# tviic2d6mddr register map
Vendor: Cypress Semiconductor; Series: tviic2d6mddr; File version: 1.0
CPU: CM7 r0p1, little endian, MPU, FPU, VTOR, 3 interrupt priority bits
Registers are 32-bit, read-write, reset 0x0 unless marked. A register's access mark holds for its fields unless they carry their own. Offsets are from the block's base; [hi:lo] are bit positions; lines under a group give offsets from that group; {n}, {i} and the like mark numbered series.

## VIDEOSS0 (part 14 of 18) — Video and Graphics Subsystem IP
Base 0x40A00000
0x80000 VIDEOIO group — Video I/O Core
  0x24000 DISENG1 group — Display Engine
    0x2000 FRAMEGEN1 group — Frame Generator
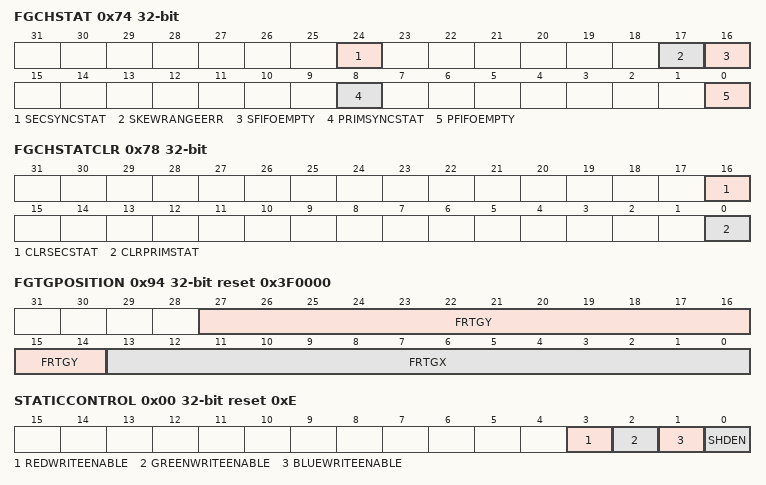
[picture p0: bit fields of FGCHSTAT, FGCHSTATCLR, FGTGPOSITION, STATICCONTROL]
      0x74 FGCHSTAT ro — FrameGen Channel Status Register
        [24] SECSYNCSTAT — Current status secondary channel synchronization (0 = out of sync, 1 = in sync; not locked).
        [17] SKEWRANGEERR — The secondary channel skew value has run out of the limit defined by SyncRangeLow and SyncRangeHigh. (bit locked when 1, clear by using ClrSecStat).
        [16] SFIFOEMPTY — Read request to empty secondary pixel FIFO detected. (bit locked when 1, clear by using ClrSecStat).
        [8] PRIMSYNCSTAT — Current status primary channel synchronization (0 = out of sync (frame tearing), 1 = in sync (normal operation); not locked).
        [0] PFIFOEMPTY — Read request to empty primary pixel FIFO detected. (Bit locked when 1, clear by using ClrPrimStat).
      0x78 FGCHSTATCLR wo reset not defined — FrameGen Channel Status Clear Register
        [16] CLRSECSTAT — Clears SFifoEmpty and SkewRangeErr in FgChStat register.
        [0] CLRPRIMSTAT — Clears PFifoEmpty in FgChStat register.
      0x7C FGSKEWMON ro — FrameGen Skew Monitor Register for Secondary Channel Skew Control
        [28:0] SKEWMON — Current skew value monitor for secondary channel skew control. Updated with hlast. (For debugging purposes only).
      0x80 FGSFIFOMIN ro reset not defined — FrameGen Secondary FIFO Min Fill Register
        [10:0] SFIFOMIN — Shows the minimal fill level of the secondary channel pixel FIFO. (For debugging purposes only).
      0x84 FGSFIFOMAX ro reset not defined — FrameGen Secondary FIFO Max Fill Register
        [10:0] SFIFOMAX — Shows the maximal fill level of the secondary channel pixel FIFO. (For debugging purposes only).
      0x88 FGSFIFOFILLCLR wo reset not defined — FrameGen Secondary FIFO Fill Clear Register
        [0] SFIFOFILLCLR — Write for clearing register FgSFifoMin and FgSFifoMax. (For debugging purposes only).
      0x8C FGSREPD ro — FrameGen Skew Regulation ExtraPolation Debug Register
        [28:0] EPVAL — Calculated value for line skew extrapolation in blanking. Updated with condition 'hlast AND vlast'. (For debugging purposes only)
      0x90 FGSRFTD ro — FrameGen Skew Regulation Frame Total Debug Register
        [27:0] FRTOT — Measured value for frame total measured in display clock cycles. Updated with condition 'hlast AND vlast' when first FrTot value is valid. (For debugging purposes only)
      0x94 FGTGPOSITION ro reset 0x3F0000 — Current (x,y) positions of the timing generator register in FrameGen timing generator.
        [27:14] FRTGY — Coordinated line position starting from VACT inside a total frame generated in timing generator in display clock cycles. (For debugging purposes only)
        [13:0] FRTGX — Coordinated pixel position starting from HACT inside a total line generated in timing generator in display clock cycles. (For debugging purposes only)
    0x2400 GAMMACOR1 group — Gamma Correction Unit 1
      0x00 STATICCONTROL reset 0xE — Static control settings.
        [3] REDWRITEENABLE — Write enable for the red color sampling point entries.
        [2] GREENWRITEENABLE — Write enable for the green color sampling point entries.
        [1] BLUEWRITEENABLE — Write enable for the blue color sampling point entries.
        [0] SHDEN — Enables shadowing of all RWS type registers (0=write_through, 1=shadowed).
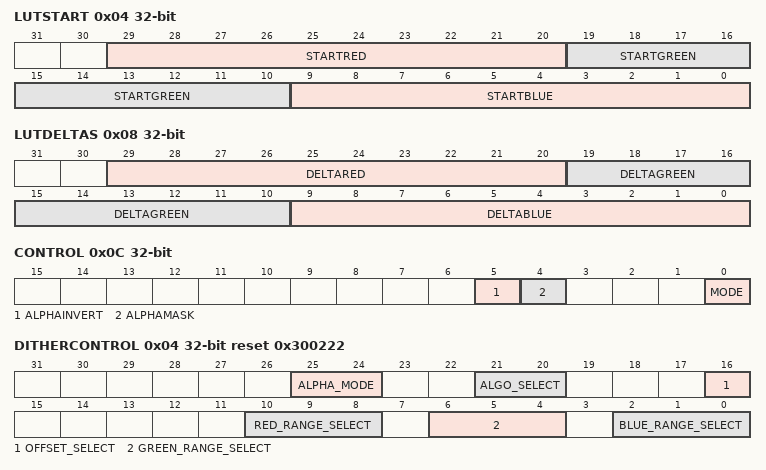
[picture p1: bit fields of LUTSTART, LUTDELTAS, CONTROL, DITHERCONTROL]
      0x04 LUTSTART wo — Start values for look-up table programming.
        [29:20] STARTRED — Start value for red or luma (Y) channel. (format is unsigned integer)
        [19:10] STARTGREEN — Start value for green or chroma (U) channel. (format is unsigned integer)
        [9:0] STARTBLUE — Start value for blue or chroma (V) channel. (format is unsigned integer)
      0x08 LUTDELTAS wo reset not defined — Delta values for look-up table programming.
        [29:20] DELTARED — Delta value for red or luma (Y) channel. (format is signed integer)
        [19:10] DELTAGREEN — Delta value for green or chroma (U) channel. (format is signed integer)
        [9:0] DELTABLUE — Delta value for blue or chroma (V) channel. (format is signed integer)
      0x0C CONTROL — Dynamic control settings.
        [5] ALPHAINVERT — Value 1 inverts the effect of the alpha mask mode when enabled (pixels with alpha value greater or equal 0.5 are by-passed).
        [4] ALPHAMASK — Value 1 enables the alpha mask mode. In this mode all pixels with an alpha value smaller than 0.5 are by-passed unchanged.
        [0] MODE — Operation mode for gamma correction unit
          0=NEUTRAL (Module in neutral mode, input data is bypassed to the output.); 1=GAMMACOR (Module in gamma correction mode.)
    0x2800 DITHER1 group — Dither Unit
      0x00 CONTROL — Dither Unit common control.
        [0] MODE — Mode which switches Dither Unit on/off. (format is unsigned integer)
          0=NEUTRAL (Neutral mode. Pixels by-pass the Dither Unit, all other settings are ignored.); 1=ACTIVE (Dither Unit is active.)
      0x04 DITHERCONTROL reset 0x300222 — Dither Unit processing control.
        [25:24] ALPHA_MODE — Enables/disables that dithering can be switched by alpha bit. (format is unsigned integer)
          0=DISABLE (The alpha bit is not considered.); 1=ENABLE_BY1 (Red, green and blue components are only dithered, if the alpha bit is 1.); 2=ENABLE_BY0 (Red, green and blue components are only dithered, if the alpha bit is 0.)
        [21:20] ALGO_SELECT — The number of output colors that can virtually be displayed by dithering is slightly lower than the number of physical input colors. This field selects how the mapping is done. (format is unsigned integer)
          1=NO_CORRECTION (Best possible resolution for most dark colors. Adds a diminutive offset to overall image brightness.); 2=BRIGHTNESS_CORRECTION (Preserves overall image brightness. Cannot resolve most dark and most bright colors. All codes in-between are distributed perfectly smooth.); 3=CONTRAST_CORRECTION (Preserves overall image brightness. Best possible distribution of color codes over complete range.)
        [16] OFFSET_SELECT — Selects the method how the dither offset is calculated. (format is unsigned integer)
          0=OFFS_SPATIAL (Offset is a bayer matrix value, which is selected according to pixel frame position.); 1=OFFS_TEMPORAL (Offset is the sum from a bayer matrix value, which is selected according to pixel frame position, and a value from a regular sequence, which changes each frame.)
        [10:8] RED_RANGE_SELECT — Mode which sets the reduction of component widths. (format is unsigned integer)
          2=RED_10TO8 (Reduces red component width from 10 bit to 8bit.); 3=RED_10TO7 (Reduces red component width from 10 bit to 7bit.); 4=RED_10TO6 (Reduces red component width from 10 bit to 6bit.); 5=RED_10TO5 (Reduces red component width from 10 bit to 5bit.)
        [6:4] GREEN_RANGE_SELECT — Mode which sets the reduction of component widths. (format is unsigned integer)
          2=GREEN_10TO8 (Reduces green component width from 10 bit to 8bit.); 3=GREEN_10TO7 (Reduces green component width from 10 bit to 7bit.); 4=GREEN_10TO6 (Reduces green component width from 10 bit to 6bit.); 5=GREEN_10TO5 (Reduces green component width from 10 bit to 5bit.)
        [2:0] BLUE_RANGE_SELECT — Mode which sets the reduction of component widths. (format is unsigned integer)
          2=BLUE_10TO8 (Reduces blue component width from 10 bit to 8bit.); 3=BLUE_10TO7 (Reduces blue component width from 10 bit to 7bit.); 4=BLUE_10TO6 (Reduces blue component width from 10 bit to 6bit.); 5=BLUE_10TO5 (Reduces blue component width from 10 bit to 5bit.)
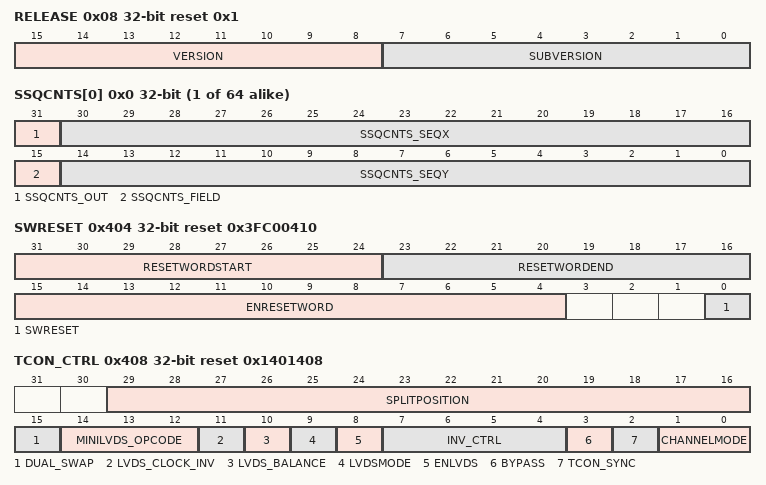
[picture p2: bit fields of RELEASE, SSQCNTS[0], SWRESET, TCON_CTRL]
      0x08 RELEASE ro reset 0x1 — Dither Unit release.
        [15:8] VERSION — Dither Unit version. (format is unsigned integer)
        [7:0] SUBVERSION — Dither Unit subversion. (format is unsigned integer)
    0x3000 TCON1 group — Timing Controller
      {0x0+4l} SSQCNTS[{l}] (l=0..63) reset not defined — The 64 Sequencer Position Definitions registers define the X/Y scan positions of the sequencers, hold their output value and assign the sequencer to an odd/even field
        [31] SSQCNTS_OUT — This bit holds the value (0,1) to be output when the X/Y scan position is reached.
        [30:16] SSQCNTS_SEQX — X scan position
        [15] SSQCNTS_FIELD — Field 0b=odd field, 1b=even field
        [14:0] SSQCNTS_SEQY — Y scan position
      0x400 SSQCYCLE — This bitfield sets the sequencer cycle length. The value set here -1 is the number of sequencer cycles
        [5:0] SSQCYCLE — Sequencer cycle length (number -1) of sequencer cycles
      0x404 SWRESET reset 0x3FC00410 — TCON Software Reset - Reset all tcon registers except configuration registers. Detailed description in specification document Note 1/ if tsig[11] pulse=n*pixel_period, (n-1)*0xFF will be blended between ResetWordStart and ResetWordEnd into miniLVDS stream Note 2/ if( EnResetWord=0) Reset-Pulse (ResetWordStart,ResetWordEnd) won't be blended into miniLVDS stream. Pixels will be transferred unchanged
        [31:24] RESETWORDSTART — 8-Bits value, that will be blended on rising edge of tsig[11] into miniLVDS stream
        [23:16] RESETWORDEND — 8-Bits value, that will be blended on falling edge of tsig[11] into miniLVDS stream
        [15:4] ENRESETWORD — Enable to blend ResetWord into miniLVDS stream EnResetWord[5-0] mapped to enable Blending Reset Pulse to [RLV5.RLV0]. EnResetWord[11-6] mapped to enable Blending Reset Pulse to [LLV5.LLV0].
        [0] SWRESET — Software reset
          0=OPERATION (operation mode); 1=SWRESET (So long SWReset = 0x1 tcon is in 'SW reset state' and it is released by internal logic (SWReset is released and end of frame arrived), read 0b reset not active 1b reset active (that means NO pixel of video frame is excepted until 'SW reset state' is released))
      0x408 TCON_CTRL reset 0x1401408 — TCON Control register
        [29:16] SPLITPOSITION — Index of first column of right display half when ChannelMode is DUAL_SPLIT. SplitPosition and (Hact - SplitPosition) must be less or equal than half of the max supported active frame width. If SplitPosition is greater than (Hact - SplitPosition), then Htotal must be greater than 2*SplitPosition; else Htotal must be greater than 2*(Hact - SplitPosition). Once setting a SplitPosition, data_en is needed. The SplitPosition must be even.
        [15] DUAL_SWAP — pixels of lower/upper channel can be swapped if tcon operates in DUAL-mode (include LVDS/miniLVDS) no effect in SINGLE-mode
          1=SWAP (swapping pixels between lower-channel and upper-channel); 0=NON_SWAP (NON-swapping pixels between lower-channel and upper-channel)
        [14:12] MINILVDS_OPCODE — Operation mode of MiniLVDS
          0=MODE_3PAIRS (MiniLVDS operates in 6 and 8 bit data, three pairs); 1=MODE_4PAIRS (Not Implemented); 2=MODE_5PAIRS (Not Implemented); 3=MODE_6PAIRS (MiniLVDS operates in 6 and 8 bit data, six pairs); {v}=RSVD{v-3} (N/A) (v=4..7)
        [11] LVDS_CLOCK_INV — Inversion the polarity of lvds clock in OpenLDI Mode
          1=INV (Invert LVDS Clock); 0=NON_INV (NON-Invert LVDS Clock)
        [10] LVDS_BALANCE — Operation mode of LVDS-OpenLDI
          1=BALANCED (LVDS operates in 24 bits Balanced Mode); 0=UNBALANCED (LVDS operates in 24 bits Unbalanced Mode)
        [9] LVDSMODE — Selection the LVDS Mode if EnLVDS = ENABLE_LVDS
          1=MINI_LVDS; 0=LVDS (LVDS Mode, refer to OpenLDI)
        [8] ENLVDS — Enable LVDS Mode
          1=ENABLE_LVDS (Enable LVDS , TTL and RSDS are disable); 0=DISABLE_LVDS (Disable LVDS, Enable TTL and RSDS)
        [7:4] INV_CTRL — Minimize the toggle rate of tcon output for display panel, that supports data inversion control. Otherwise set Inv_Ctrl = 0. Valid for all channels . Inv_Ctrl does not effect any function on LVDS-Output.
          0=DISABLE (Disable inversion control); 1=RGB_2_BITS (Enable inversion control for number of RGB-Bits = 2); 2=RGB_4_BITS (Enable inversion control for number of RGB-Bits = 4); 3=RGB_6_BITS (Enable inversion control for number of RGB-Bits = 6); 4=RGB_8_BITS (Enable inversion control for number of RGB-Bits = 8); 5=RGB_10_BITS (Enable inversion control for number of RGB-Bits = 10); 6=RGB_12_BITS (Enable inversion control for number of RGB-Bits = 12); 7=RGB_14_BITS (Enable inversion control for number of RGB-Bits = 14); 8=RGB_16_BITS (Enable inversion control for number of RGB-Bits = 16); 9=RGB_18_BITS (Enable inversion control for number of RGB-Bits = 18); 10=RGB_20_BITS (Enable inversion control for number of RGB-Bits = 20); 11=RGB_22_BITS (Enable inversion control for number of RGB-Bits = 22); 12=RGB_24_BITS (Enable inversion control for number of RGB-Bits = 24); 13=RSVD1 (N/A); 14=RSVD2 (N/A); 15=RSVD3 (N/A)
        [3] BYPASS — Bypassing synchronization
          0=TCON_MODE (tcon operation mode); 1=BYPASS_MODE (tcon in Bypass mode. input pixel and its sync-signals are bypassed to tcon-output)
        [2] TCON_SYNC — Select synchronization between hsync/vsync and hlast/vlast
          0=H_VLAST (tcon timing generator synchronized to hlast, vlast); 1=H_VSYNC (tcon timing generator synchronized to hsync, vsync where horizontal synchronization is synchronized at the falling edge of hsync)
        [1:0] CHANNELMODE — Selects one of tcon operation modes, SINGLE, DUAL_INTERLEAVED or DUAL_SPLIT. If MiniLVDS operation is selected (EnLVDS = ENABLE_LVDS and LVDSMode = Mini_LVDS), tcon operates in MiniLVDS mode, independent of ChannelMode programming. SplitPosition must be specified in MiniLVDS operation in DUAL_INTERLEAVED or DUAL_SPLIT mode, the horizontal parameter of signal generator have to set twice as they are specified in the panel-specification (panel 320, tsig_start 0, tsig_stop 320 on DUAL-Mode tsig_start 0, tsig_stop 640 ... (SplitPosition is automatically adjusted) )
          0=SINGLE (Single pixel mode. Both channels channel are active at full pixel clock. If bitmap of both panels are the same, both panels are identical); 1=DUAL_INTERLEAVED (Dual pixel mode. Both channels are active at half the pixel clock. 1st channel drives display columns with even and 2nd one with odd index.); 2=DUAL_SPLIT (Dual pixel mode. Both channels are active at half the pixel clock. 1st channel drives the left and 2nd one the right half of the display. Note data_en is needed in this mode)
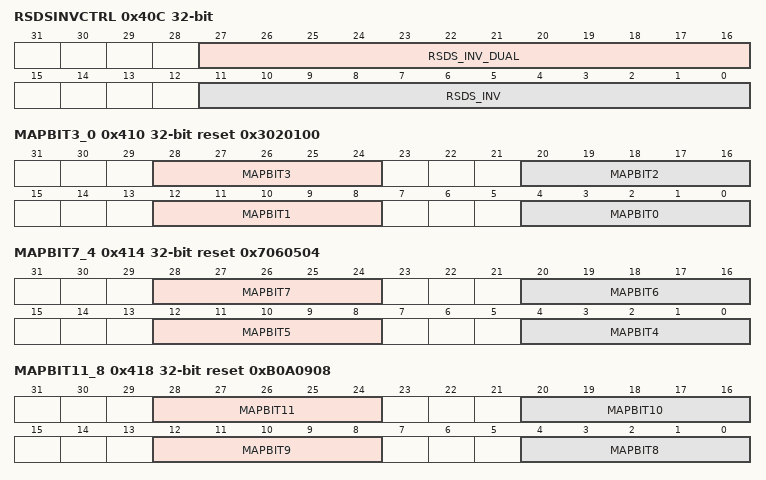
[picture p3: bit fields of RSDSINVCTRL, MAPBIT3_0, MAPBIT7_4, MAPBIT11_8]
      0x40C RSDSINVCTRL — Controls inversion of output polarity when connected IO cells operate in RSDS mode
        [27:16] RSDS_INV_DUAL — Same as RSDS_inv for 2nd channel
        [11:0] RSDS_INV — Inversion vector for 1st channel. For i in [ 0 .. 11 ]; if RSDS_Inv [ i ] == 0 => NON-Inversion of RSDS [ i ] else Inversion of RSDS [ i ]
      0x410 MAPBIT3_0 reset 0x3020100 — Mapping of 24 bit RGB or Timing Generator TSig[5-0] to bit 0 .. 3
        [28:24] MAPBIT3 — map bit[ 3 ] from [ Blue, Green, Red ] or from TSig[5-0]. If MapBit3 in [ 23..0 ] => bit[ 3 ] = [ Blue, Green, Red ] [ MapBit3 ]; if MapBit3 in [29 .. 24] => bit[ 3 ] in { TSig[5] .. TSig[0] }; If MapBit3 = 31 => bit[ 3 ] = 0 ; if MapBit3= 30 => bit[ 3 ] = 1
        [20:16] MAPBIT2 — map bit[ 2 ] from [ Blue, Green, Red ] or from TSig[5-0]. If MapBit2 in [ 23..0 ] => bit[ 2 ] = [ Blue, Green, Red ] [ MapBit2 ]; if MapBit2 in [29 .. 24] => bit[ 2 ] in { TSig[5] .. TSig[0] }; If MapBit2 = 31 => bit[ 2 ] = 0 ; if MapBit2= 30 => bit[ 2 ] = 1
        [12:8] MAPBIT1 — map bit[ 1 ] from [ Blue, Green, Red ] or from TSig[5-0]. If MapBit1 in [ 23..0 ] => bit[ 1 ] = [ Blue, Green, Red ] [ MapBit1 ]; if MapBit1 in [29 .. 24] => bit[ 1 ] in { TSig[5] .. TSig[0] }; If MapBit1 = 31 => bit[ 1 ] = 0 ; if MapBit1= 30 => bit[ 1 ] = 1
        [4:0] MAPBIT0 — map bit[ 0 ] from [ Blue, Green, Red ] or from TSig[5-0]. If MapBit0 in [ 23..0 ] => bit[ 0 ] = [ Blue, Green, Red ] [ MapBit0 ]; if MapBit0 in [29 .. 24] => bit[ 0 ] in { TSig[5] .. TSig[0] }; If MapBit0 = 31 => bit[ 0 ] = 0 ; if MapBit1= 30 => bit[ 0 ] = 1
      0x414 MAPBIT7_4 reset 0x7060504 — Mapping of 24 bit RGB or Timing Generator TSig[5-0] to bit 4 .. 7
        [28:24] MAPBIT7 — map bit[ 7 ] from [ Blue, Green, Red ] or from TSig[5-0]. If MapBit7 in [ 23..0 ] => bit[ 7 ] = [ Blue, Green, Red ] [ MapBit7 ]; if MapBit7 in [29 .. 24] => bit[ 7 ] in { TSig[5] .. TSig[0] }; If MapBit7 = 31 => bit[ 7 ] = 0 ; if MapBit7= 30 => bit[ 7 ] = 1
        [20:16] MAPBIT6 — map bit[ 6 ] from [ Blue, Green, Red ] or from TSig[5-0]. If MapBit6 in [ 23..0 ] => bit[ 6 ] = [ Blue, Green, Red ] [ MapBit6 ]; if MapBit6 in [29 .. 24] => bit[ 6 ] in { TSig[5] .. TSig[0] }; If MapBit6 = 31 => bit[ 6 ] = 0 ; if MapBit6= 30 => bit[ 6 ] = 1
        [12:8] MAPBIT5 — map bit[ 5 ] from [ Blue, Green, Red ] or from TSig[5-0]. If MapBit5 in [ 23..0 ] => bit[ 5 ] = [ Blue, Green, Red ] [ MapBit5 ]; if MapBit5 in [29 .. 24] => bit[ 5 ] in { TSig[5] .. TSig[0] }; If MapBit5 = 31 => bit[ 5 ] = 0 ; if MapBit5= 30 => bit[ 5 ] = 1
        [4:0] MAPBIT4 — map bit[ 4 ] from [ Blue, Green, Red ] or from TSig[5-0]. If MapBit4 in [ 23..0 ] => bit[ 4 ] = [ Blue, Green, Red ] [ MapBit4 ]; if MapBit4 in [29 .. 24] => bit[ 4 ] in { TSig[5] .. TSig[0] }; If MapBit4 = 31 => bit[ 4 ] = 0 ; if MapBit4= 30 => bit[ 4 ] = 1
      0x418 MAPBIT11_8 reset 0xB0A0908 — Mapping of 24 bit RGB or Timing Generator TSig[5-0] to bit 8 .. 11
        [28:24] MAPBIT11 — map bit[ 11 ] from [ Blue, Green, Red ] or from TSig[5-0]. If MapBit11 in [ 23..0 ] => bit[ 11 ] = [ Blue, Green, Red ] [ MapBit11 ]; if MapBit11 in [29 .. 24] => bit[ 11 ] in { TSig[5] .. TSig[0] } ; If MapBit11 = 31 => bit[ 11 ] = 0 ; if MapBit11= 30 => bit[ 11 ] = 1
        [20:16] MAPBIT10 — map bit[ 10 ] from [ Blue, Green, Red ] or from TSig[5-0]. If MapBit10 in [ 23..0 ] => bit[ 10 ] = [ Blue, Green, Red ] [ MapBit10 ]; if MapBit10 in [29 .. 24] => bit[ 10 ] in { TSig[5] .. TSig[0] } ; If MapBit10 = 31 => bit[ 10 ] = 0 ; if MapBit10= 30 => bit[ 10 ] = 1
        [12:8] MAPBIT9 — map bit[ 9 ] from [ Blue, Green, Red ] or from TSig[5-0]. if MapBit9 in [ 23..0 ] => bit[ 9 ] = [ Blue, Green, Red ] [ MapBit9 ]; if MapBit9 in [29 .. 24] => bit[ 9 ] in { TSig[5] .. TSig[0] }; If MapBit9 = 31 => bit[ 9 ] = 0 ; if MapBit9= 30 => bit[ 9 ] = 1
        [4:0] MAPBIT8 — map bit[ 8 ] from [ Blue, Green, Red ] or from TSig[5-0]. if MapBit8 in [ 23..0 ] => bit[ 8 ] = [ Blue, Green, Red ] [ MapBit8 ]; if MapBit8 in [29 .. 24] => bit[ 8 ] in { TSig[5] .. TSig[0] }; If MapBit8 = 31 => bit[ 8 ] = 0 ; if MapBit8= 30 => bit[ 8 ] = 1
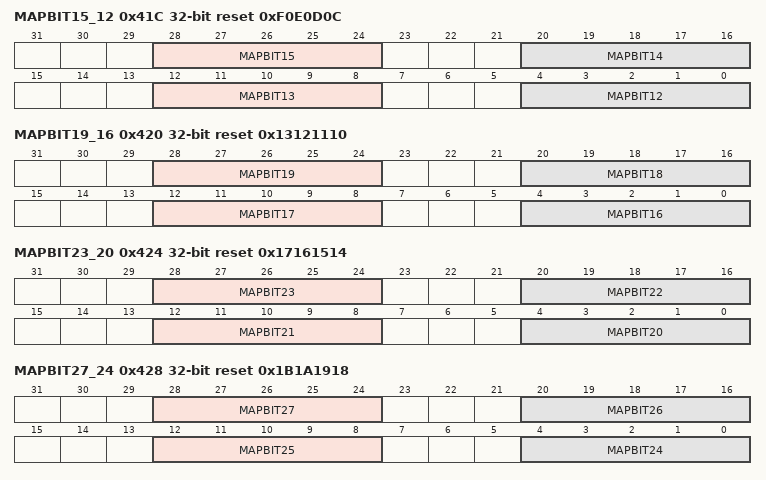
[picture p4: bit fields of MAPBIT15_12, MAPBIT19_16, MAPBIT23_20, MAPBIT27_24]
      0x41C MAPBIT15_12 reset 0xF0E0D0C — Mapping of 24 bit RGB or Timing Generator TSig[5-0] to bit 12 .. 15
        [28:24] MAPBIT15 — map bit[ 15 ] from [ Blue, Green, Red ] or from TSig[5-0]. If MapBit15 in [ 23..0 ] => bit[ 15 ] = [ Blue, Green, Red ] [ MapBit15 ]; if MapBit15 in [29 .. 24] => bit[ 15 ] in { TSig[5] .. TSig[0] } ; If MapBit15 = 31 => bit[ 15 ] = 0 ; if MapBit15= 30 => bit[ 15 ] = 1
        [20:16] MAPBIT14 — map bit[ 14 ] from [ Blue, Green, Red ] or from TSig[5-0]. If MapBit14 in [ 23..0 ] => bit[ 14 ] = [ Blue, Green, Red ] [ MapBit14 ]; if MapBit14 in [29 .. 24] => bit[ 14 ] in { TSig[5] .. TSig[0] } ; If MapBit14 = 31 => bit[ 14 ] = 0 ; if MapBit14= 30 => bit[ 14 ] = 1
        [12:8] MAPBIT13 — map bit[ 13 ] from [ Blue, Green, Red ] or from TSig[5-0]. If MapBit13 in [ 23..0 ] => bit[ 13 ] = [ Blue, Green, Red ] [ MapBit13 ]; if MapBit13 in [29 .. 24] => bit[ 13 ] in { TSig[5] .. TSig[0] } ; If MapBit13 = 31 => bit[ 13 ] = 0 ; if MapBit13= 30 => bit[ 13 ] = 1
        [4:0] MAPBIT12 — map bit[ 12 ] from [ Blue, Green, Red ] or from TSig[5-0]. If MapBit12 in [ 23..0 ] => bit[ 12 ] = [ Blue, Green, Red ] [ MapBit12 ]; if MapBit12 in [29 .. 24] => bit[ 12 ] in { TSig[5] .. TSig[0] } ; If MapBit12 = 31 => bit[ 12 ] = 0 ; if MapBit12= 30 => bit[ 12 ] = 1
      0x420 MAPBIT19_16 reset 0x13121110 — Mapping of 24 bit RGB or Timing Generator TSig[5-0] to bit 16 .. 19
        [28:24] MAPBIT19 — map bit[ 19 ] from [ Blue, Green, Red ] or from TSig[5-0]. If MapBit19 in [ 23..0 ] => bit[ 19 ] = [ Blue, Green, Red ] [ MapBit19 ]; if MapBit19 in [29 .. 24] => bit[ 19 ] in { TSig[5] .. TSig[0] } ; If MapBit19 = 31 => bit[ 19 ] = 0 ; if MapBit19= 30 => bit[ 19 ] = 1
        [20:16] MAPBIT18 — map bit[ 18 ] from [ Blue, Green, Red ] or from TSig[5-0]. If MapBit18 in [ 23..0 ] => bit[ 18 ] = [ Blue, Green, Red ] [ MapBit18 ]; if MapBit18 in [29 .. 24] => bit[ 18 ] in { TSig[5] .. TSig[0] } ; If MapBit18 = 31 => bit[ 18 ] = 0 ; if MapBit18= 30 => bit[ 18 ] = 1
        [12:8] MAPBIT17 — map bit[ 17 ] from [ Blue, Green, Red ] or from TSig[5-0]. If MapBit17 in [ 23..0 ] => bit[ 17 ] = [ Blue, Green, Red ] [ MapBit17 ]; if MapBit17 in [29 .. 24] => bit[ 17 ] in { TSig[5] .. TSig[0] } ; If MapBit17 = 31 => bit[ 17 ] = 0 ; if MapBit17= 30 => bit[ 17 ] = 1
        [4:0] MAPBIT16 — map bit[ 16 ] from [ Blue, Green, Red ] or from TSig[5-0]. If MapBit16 in [ 23..0 ] => bit[ 16 ] = [ Blue, Green, Red ] [ MapBit16 ]; if MapBit16 in [29 .. 24] => bit[ 16 ] in { TSig[5] .. TSig[0] } ; If MapBit16 = 31 => bit[ 16 ] = 0 ; if MapBit16= 30 => bit[ 16 ] = 1
      0x424 MAPBIT23_20 reset 0x17161514 — Mapping of 24 bit RGB or Timing Generator TSig[5-0] to bit 20 .. 23
        [28:24] MAPBIT23 — map bit[ 23 ] from [ Blue, Green, Red ] or from TSig[5-0]. If MapBit23 in [ 23..0 ] => bit[ 23 ] = [ Blue, Green, Red ] [ MapBit23 ]; if MapBit23 in [29 .. 24] => bit[ 23 ] in { TSig[5] .. TSig[0] } ; If MapBit23 = 31 => bit[ 23 ] = 0 ; if MapBit23= 30 => bit[ 23 ] = 1
        [20:16] MAPBIT22 — map bit[ 22 ] from [ Blue, Green, Red ] or from TSig[5-0]. If MapBit22 in [ 23..0 ] => bit[ 22 ] = [ Blue, Green, Red ] [ MapBit22 ]; if MapBit22 in [29 .. 24] => bit[ 22 ] in { TSig[5] .. TSig[0] } ; If MapBit22 = 31 => bit[ 22 ] = 0 ; if MapBit22= 30 => bit[ 22 ] = 1
        [12:8] MAPBIT21 — map bit[ 21 ] from [ Blue, Green, Red ] or from TSig[5-0]. If MapBit21 in [ 23..0 ] => bit[ 21 ] = [ Blue, Green, Red ] [ MapBit21 ]; if MapBit21 in [29 .. 24] => bit[ 21 ] in { TSig[5] .. TSig[0] } ; If MapBit21 = 31 => bit[ 21 ] = 0 ; if MapBit21= 30 => bit[ 21 ] = 1
        [4:0] MAPBIT20 — map bit[ 20 ] from [ Blue, Green, Red ] or from TSig[5-0]. If MapBit20 in [ 23..0 ] => bit[ 20 ] = [ Blue, Green, Red ] [ MapBit20 ]; if MapBit20 in [29 .. 24] => bit[ 20 ] in { TSig[5] .. TSig[0] } ; If MapBit20 = 31 => bit[ 20 ] = 0 ; if MapBit20= 30 => bit[ 20 ] = 1
      0x428 MAPBIT27_24 reset 0x1B1A1918 — Mapping of 24 bit RGB or Timing Generator TSig[5-0] to bit 24 .. 27
        [28:24] MAPBIT27 — map bit[27] from [ Blue, Green, Red ] or from TSig[5-0]. If MapBit27 in [ 23..0 ] => bit[27] = [ Blue, Green, Red ] [ MapBit27 ]; if MapBit27 in [29 .. 24] => bit[27] in { TSig[5] .. TSig[0] } ; If MapBit27 = 31 => bit[27] = 0 ; if MapBit27= 30 => bit[27] = 1
        [20:16] MAPBIT26 — map bit[26] from [ Blue, Green, Red ] or from TSig[5-0]. If MapBit26 in [ 23..0 ] => bit[26] = [ Blue, Green, Red ] [ MapBit26 ]; if MapBit26 in [29 .. 24] => bit[26] in { TSig[5] .. TSig[0] } ; If MapBit26 = 31 => bit[26] = 0 ; if MapBit26= 30 => bit[26] = 1
        [12:8] MAPBIT25 — map bit[25] from [ Blue, Green, Red ] or from TSig[5-0]. If MapBit25 in [ 23..0 ] => bit[25] = [ Blue, Green, Red ] [ MapBit25 ]; if MapBit25 in [29 .. 24] => bit[25] in { TSig[5] .. TSig[0] } ; If MapBit25 = 31 => bit[25] = 0 ; if MapBit25= 30 => bit[25] = 1
        [4:0] MAPBIT24 — map bit[24] from [ Blue, Green, Red ] or from TSig[5-0]. If MapBit24 in [ 23..0 ] => bit[24] = [ Blue, Green, Red ] [ MapBit24 ]; if MapBit24 in [29 .. 24] => bit[24] in { TSig[5] .. TSig[0] } ; If MapBit24 = 31 => bit[24] = 0 ; if MapBit24= 30 => bit[24] = 1
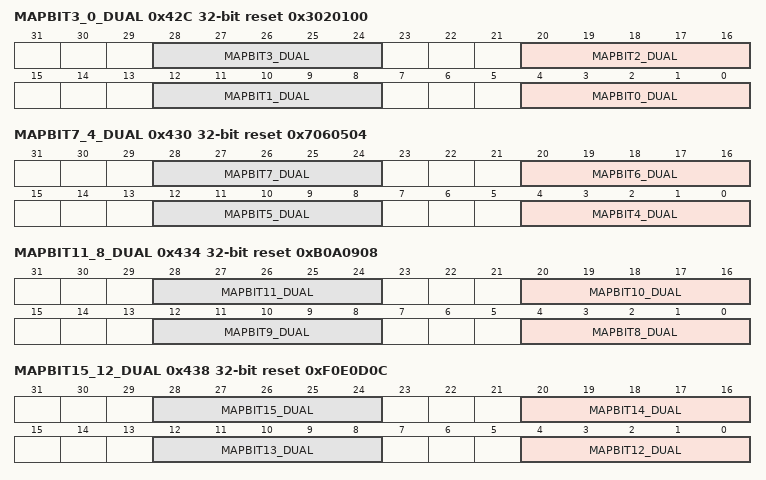
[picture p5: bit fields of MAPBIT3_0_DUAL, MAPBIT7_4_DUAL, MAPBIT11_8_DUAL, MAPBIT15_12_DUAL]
      0x42C MAPBIT3_0_DUAL reset 0x3020100 — Same as MapBit3_0 for 2nd channel
        [8n+4:8n] MAPBIT{n}_DUAL (n=0..3) — Same as MapBit{n} for 2nd channel
      0x430 MAPBIT7_4_DUAL reset 0x7060504 — Same as MapBit7_4 for 2nd channel
        [8n-28:8n-32] MAPBIT{n}_DUAL (n=4..7) — Same as MapBit{n} for 2nd channel
      0x434 MAPBIT11_8_DUAL reset 0xB0A0908 — Same as MapBit11_8 for 2nd channel
        [8n-60:8n-64] MAPBIT{n}_DUAL (n=8..11) — Same as MapBit{n} for 2nd channel
      0x438 MAPBIT15_12_DUAL reset 0xF0E0D0C — Same as MapBit15_12 for 2nd channel
        [8n-92:8n-96] MAPBIT{n}_DUAL (n=12..15) — Same as MapBit{n} for 2nd channel
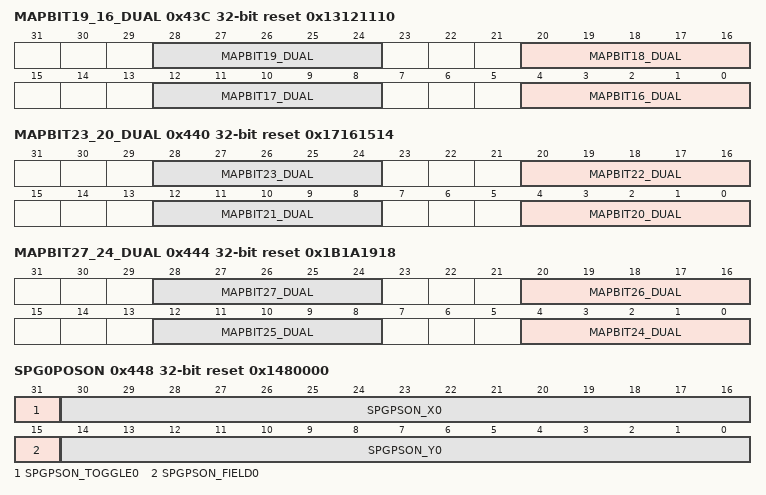
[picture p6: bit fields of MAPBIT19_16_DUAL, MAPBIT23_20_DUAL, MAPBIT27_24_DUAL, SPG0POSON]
      0x43C MAPBIT19_16_DUAL reset 0x13121110 — Same as MapBit19_16 for 2nd channel
        [8n-124:8n-128] MAPBIT{n}_DUAL (n=16..19) — Same as MapBit{n} for 2nd channel
      0x440 MAPBIT23_20_DUAL reset 0x17161514 — Same as MapBit23_20 for 2nd channel
        [8n-156:8n-160] MAPBIT{n}_DUAL (n=20..23) — Same as MapBit{n} for 2nd channel
      0x444 MAPBIT27_24_DUAL reset 0x1B1A1918 — Same as MapBit27_24 for 2nd channel
        [8n-188:8n-192] MAPBIT{n}_DUAL (n=24..27) — Same as MapBit{n} for 2nd channel
      0x448 SPG0POSON reset 0x1480000 — Sync pulse generator 0, 'Switch on' position
        [31] SPGPSON_TOGGLE0 — Toggle enable 0b=disable, 1b=enable
        [30:16] SPGPSON_X0 — X scan position
        [15] SPGPSON_FIELD0 — Field 0b=odd field, 1b=even field
        [14:0] SPGPSON_Y0 — Y scan position
      0x44C SPG0MASKON reset 0xFFFF — The Sequencer Pulse Generator 0 Mask Enable register is used to mask the enable of SPG 0
        [30:0] SPGMKON0 — Mask bits 0b=Include this bit in position matching, 1b= Do not include this bit in position matching
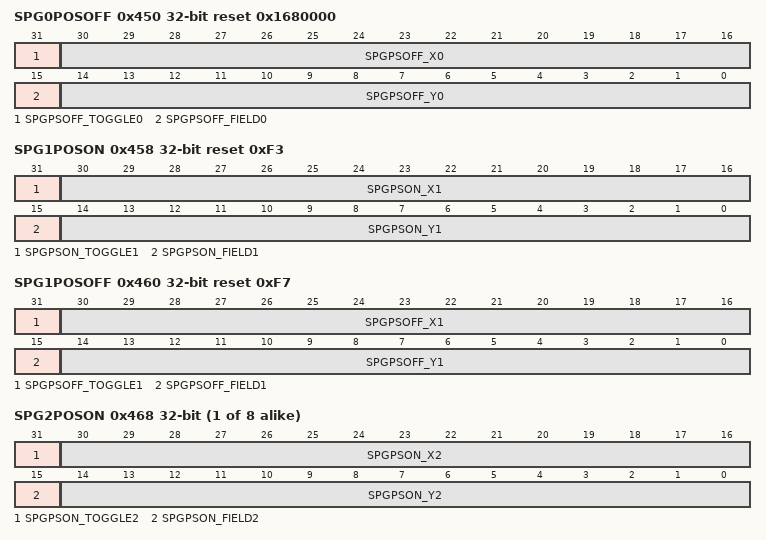
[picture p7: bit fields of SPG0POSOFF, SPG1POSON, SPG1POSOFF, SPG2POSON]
      0x450 SPG0POSOFF reset 0x1680000 — Sync pulse generator 0, 'Switch off' position
        [31] SPGPSOFF_TOGGLE0 — Toggle enable 0b=disable, 1b=enable
        [30:16] SPGPSOFF_X0 — X scan position
        [15] SPGPSOFF_FIELD0 — Field 0b=odd field, 1b=even field
        [14:0] SPGPSOFF_Y0 — Y scan position
      0x454 SPG0MASKOFF reset 0xFFFF — The Sequencer Pulse Generator 0 Mask Enable register is used to mask the disable of SPG 0
        [30:0] SPGMKOFF0 — Mask bits 0b=Include this bit in position matching, 1b= Do not include this bit in position matching
      0x458 SPG1POSON reset 0xF3 — Sync pulse generator 1, 'Switch on' position
        [31] SPGPSON_TOGGLE1 — Toggle enable 0b=disable, 1b=enable
        [30:16] SPGPSON_X1 — X scan position
        [15] SPGPSON_FIELD1 — Field 0b=odd field, 1b=even field
        [14:0] SPGPSON_Y1 — Y scan position
      0x45C SPG1MASKON reset 0x7FFF0000 — The Sequencer Pulse Generator 1 Mask Enable register is used to mask the enable of SPG 1
        [30:0] SPGMKON1 — mask bits (1= do not include this bit into position matching)
      0x460 SPG1POSOFF reset 0xF7 — Sync pulse generator 1, 'Switch off' position
        [31] SPGPSOFF_TOGGLE1 — Toggle enable 0b=disable, 1b=enable
        [30:16] SPGPSOFF_X1 — X scan position
        [15] SPGPSOFF_FIELD1 — Field 0b=odd field, 1b=even field
        [14:0] SPGPSOFF_Y1 — Y scan position
      0x464 SPG1MASKOFF reset 0x7FFF0000 — The Sequencer Pulse Generator 1 Mask Enable register is used to mask the disable of SPG 1
        [30:0] SPGMKOFF1 — Mask bits 0b=Include this bit in position matching, 1b= Do not include this bit in position matching
      {0x448+0x10*l} SPG{l}POSON (l=2..9) — Sync pulse generator {l}, 'Switch on' position
        [31] SPGPSON_TOGGLE{l} — Toggle enable 0b=disable, 1b=enable
        [30:16] SPGPSON_X{l} — X scan position
        [15] SPGPSON_FIELD{l} — Field 0b=odd field, 1b=even field
        [14:0] SPGPSON_Y{l} — Y scan position
      0x46C SPG2MASKON reset 0xFFFF — The Sequencer Pulse Generator 2 Mask Enable register is used to mask the enable of SPG 2
        [30:0] SPGMKON2 — Mask bits 0b=Include this bit in position matching, 1b= Do not include this bit in position matching
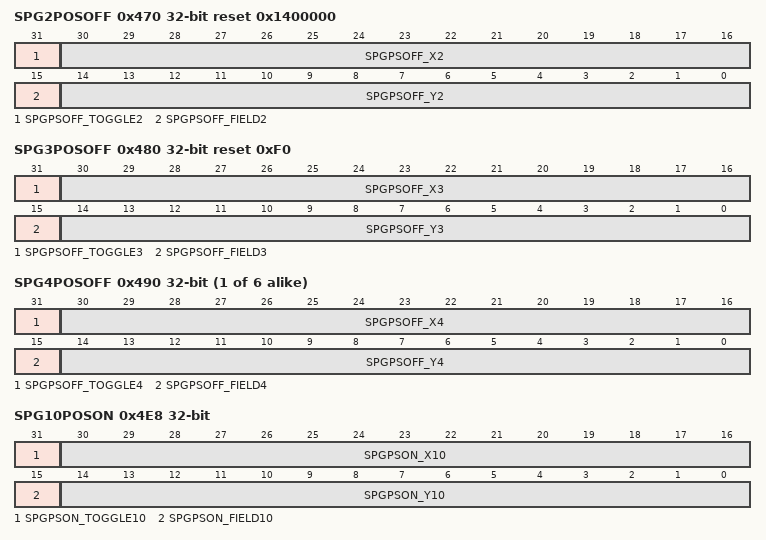
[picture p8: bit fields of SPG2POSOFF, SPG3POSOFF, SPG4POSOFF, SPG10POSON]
      0x470 SPG2POSOFF reset 0x1400000 — Sync pulse generator 2, 'Switch off' position
        [31] SPGPSOFF_TOGGLE2 — Toggle enable 0b=disable, 1b=enable
        [30:16] SPGPSOFF_X2 — X scan position
        [15] SPGPSOFF_FIELD2 — Field 0b=odd field, 1b=even field
        [14:0] SPGPSOFF_Y2 — Y scan position
      0x474 SPG2MASKOFF reset 0xFFFF — The Sequencer Pulse Generator 2 Mask Enable register is used to mask the disable of SPG 2
        [30:0] SPGMKOFF2 — Mask bits 0b=Include this bit in position matching, 1b= Do not include this bit in position matching
      0x47C SPG3MASKON reset 0x7FFF0000 — The Sequencer Pulse Generator 3 Mask Enable register is used to mask the enable of SPG 3
        [30:0] SPGMKON3 — Mask bits 0b=Include this bit in position matching, 1b= Do not include this bit in position matching
      0x480 SPG3POSOFF reset 0xF0 — Sync pulse generator 3, 'Switch off' position
        [31] SPGPSOFF_TOGGLE3 — Toggle enable 0b=disable, 1b=enable
        [30:16] SPGPSOFF_X3 — X scan position
        [15] SPGPSOFF_FIELD3 — Field 0b=odd field, 1b=even field
        [14:0] SPGPSOFF_Y3 — Y scan position
      0x484 SPG3MASKOFF reset 0x7FFF0000 — The Sequencer Pulse Generator 3 Mask Enable register is used to mask the disable of SPG 3
        [30:0] SPGMKOFF3 — Mask bits 0b=Include this bit in position matching, 1b= Do not include this bit in position matching
      {0x44C+0x10*l} SPG{l}MASKON (l=4..11) — The Sequencer Pulse Generator {l} Mask Enable register is used to mask the enable of SPG {l}
        [30:0] SPGMKON{l} — Mask bits 0b=Include this bit in position matching, 1b= Do not include this bit in position matching
      {0x450+0x10*l} SPG{l}POSOFF (l=4..9) — Sync pulse generator {l}, 'Switch off' position
        [31] SPGPSOFF_TOGGLE{l} — Toggle enable 0b=disable, 1b=enable
        [30:16] SPGPSOFF_X{l} — X scan position
        [15] SPGPSOFF_FIELD{l} — Field 0b=odd field, 1b=even field
        [14:0] SPGPSOFF_Y{l} — Y scan position
      {0x454+0x10*l} SPG{l}MASKOFF (l=4..11) — The Sequencer Pulse Generator {l} Mask Enable register is used to mask the disable of SPG {l}
        [30:0] SPGMKOFF{l} — Mask bits 0b=Include this bit in position matching, 1b= Do not include this bit in position matching
      0x4E8 SPG10POSON — Sync pulse generator 10, 'Switch on' position
        [31] SPGPSON_TOGGLE10 — toggle enable 0b=disable, 1b=enable
        [30:16] SPGPSON_X10 — X scan position
        [15] SPGPSON_FIELD10 — Field 0b=odd field, 1b=even field
        [14:0] SPGPSON_Y10 — Y scan position
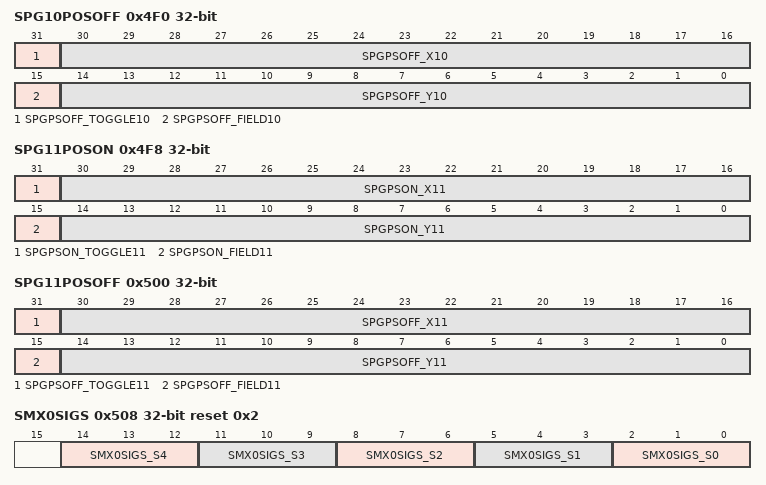
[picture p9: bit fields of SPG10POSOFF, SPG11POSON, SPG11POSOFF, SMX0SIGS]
      0x4F0 SPG10POSOFF — Sync pulse generator 10, 'Switch off' position
        [31] SPGPSOFF_TOGGLE10 — toggle enable 0b=disable, 1b=enable
        [30:16] SPGPSOFF_X10 — X scan position
        [15] SPGPSOFF_FIELD10 — Field 0b=odd field, 1b=even field
        [14:0] SPGPSOFF_Y10 — Y scan position
      0x4F8 SPG11POSON — Sync pulse generator 11, 'Switch on' position
        [31] SPGPSON_TOGGLE11 — toggle enable 0b=disable, 1b=enable
        [30:16] SPGPSON_X11 — X scan position
        [15] SPGPSON_FIELD11 — Field 0b=odd field, 1b=even field
        [14:0] SPGPSON_Y11 — Y scan position
      0x500 SPG11POSOFF — Sync pulse generator 11, 'Switch off' position
        [31] SPGPSOFF_TOGGLE11 — toggle enable 0b=disable, 1b=enable
        [30:16] SPGPSOFF_X11 — X scan position
        [15] SPGPSOFF_FIELD11 — Field 0b=odd field, 1b=even field
        [14:0] SPGPSOFF_Y11 — Y scan position
      0x508 SMX0SIGS reset 0x2 — Selection of input signals of sync mixer
        [3n+2:3n] SMX0SIGS_S{n} (n=0..4) — select {n} 000b=constant 0, 001b=sync sequencer output, 010b...111b sync pulse generator SPG0 .. SPG5
      0x50C SMX0FCTTABLE reset 0x1 — The sync mixer output is the result of the function table a=s4*2**4+s3*2**3+s2*2**2+s1*2**1+s0*2**0 whereby a is bit number and s result of sync mixer input selection
        [31:0] SMXFCT0 — Sync mixer 0 function table
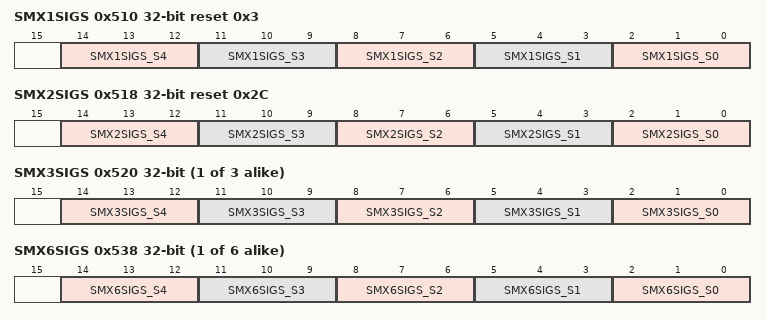
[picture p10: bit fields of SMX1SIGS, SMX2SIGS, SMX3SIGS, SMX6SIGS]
      0x510 SMX1SIGS reset 0x3 — Selection of input signals of sync mixer
        [3n+2:3n] SMX1SIGS_S{n} (n=0..4) — select {n} 000b=constant 0, 001b=sync sequencer output, 010b...111b sync pulse generator SPG0 .. SPG5
      0x514 SMX1FCTTABLE reset 0x1 — The sync mixer output is the result of the function table a=s4*2**4+s3*2**3+s2*2**2+s1*2**1+s0*2**0 whereby a is bit number and s result of sync mixer input selection
        [31:0] SMXFCT1 — Sync mixer 1 function table
      0x518 SMX2SIGS reset 0x2C — Selection of input signals of sync mixer
        [3n+2:3n] SMX2SIGS_S{n} (n=0..4) — select {n} 000b=constant 0, 001b=sync sequencer output, 010b...111b sync pulse generator SPG0 .. SPG5
      0x51C SMX2FCTTABLE reset 0x8 — The sync mixer output is the result of the function table a=s4*2**4+s**3*2**3+s2*2**2+s1*2**1+s0*2**0 whereby a is bit number and s result of sync mixer input selection
        [31:0] SMXFCT2 — Sync mixer 2 function table
      {0x508+8l} SMX{l}SIGS (l=3..5) — Selection of input signals of sync mixer
        [3n+2:3n] SMX{l}SIGS_S{n} (n=0..4) — select {n} 000b=constant 0, 001b=sync sequencer output, 010b...111b sync pulse generator SPG0 .. SPG5
      {0x50C+8l} SMX{l}FCTTABLE (l=3..11) — The sync mixer output is the result of the function table a=s4*2**4+s3*2**3+s2*2**2+s1*2**1+s0*2**0 whereby a is bit number and s result of sync mixer input selection
        [31:0] SMXFCT{l} — Sync mixer {l} function table
      {0x508+8l} SMX{l}SIGS (l=6..11) — Selection of input signals of sync mixer
        [3n+2:3n] SMX{l}SIGS_S{n} (n=0..4) — select {n} 000b=constant 0, 001b=sync sequencer output, 010b...111b sync pulse generator SPG6 .. SPG11
